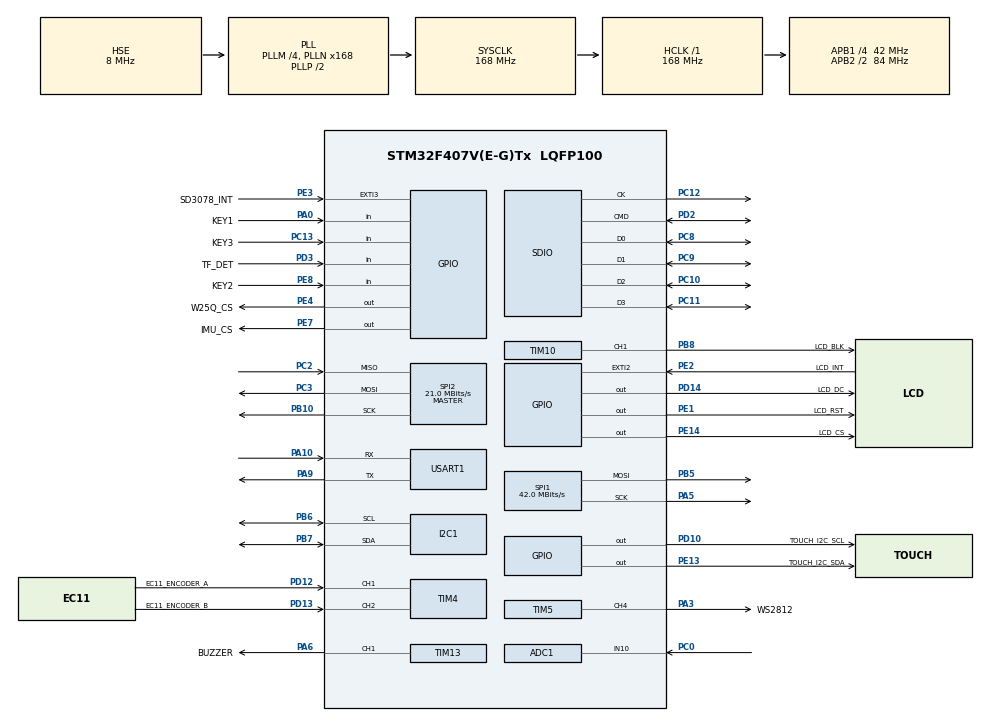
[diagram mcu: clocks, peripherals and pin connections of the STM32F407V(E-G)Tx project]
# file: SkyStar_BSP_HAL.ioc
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ADC1.Channel-0\#ChannelRegularConversion=ADC_CHANNEL_10
ADC1.NbrOfConversionFlag=1
ADC1.Rank-0\#ChannelRegularConversion=1
ADC1.SamplingTime-0\#ChannelRegularConversion=ADC_SAMPLETIME_3CYCLES
ADC1.master=1
Dma.Request0=USART1_RX
Dma.Request1=USART1_TX
Dma.Request2=TIM5_CH4/TRIG
Dma.Request3=SPI1_TX
Dma.Request4=SDIO_RX
Dma.Request5=SDIO_TX
Dma.SDIO_RX.4.Direction=DMA_PERIPH_TO_MEMORY
Dma.SDIO_RX.4.FIFOMode=DMA_FIFOMODE_ENABLE
Dma.SDIO_RX.4.FIFOThreshold=DMA_FIFO_THRESHOLD_FULL
Dma.SDIO_RX.4.Instance=DMA2_Stream6
Dma.SDIO_RX.4.MemBurst=DMA_MBURST_INC4
Dma.SDIO_RX.4.MemDataAlignment=DMA_MDATAALIGN_WORD
Dma.SDIO_RX.4.MemInc=DMA_MINC_ENABLE
Dma.SDIO_RX.4.Mode=DMA_PFCTRL
Dma.SDIO_RX.4.PeriphBurst=DMA_PBURST_INC4
Dma.SDIO_RX.4.PeriphDataAlignment=DMA_PDATAALIGN_WORD
Dma.SDIO_RX.4.PeriphInc=DMA_PINC_DISABLE
Dma.SDIO_RX.4.Priority=DMA_PRIORITY_LOW
Dma.SDIO_TX.5.Direction=DMA_MEMORY_TO_PERIPH
Dma.SDIO_TX.5.FIFOMode=DMA_FIFOMODE_ENABLE
Dma.SDIO_TX.5.FIFOThreshold=DMA_FIFO_THRESHOLD_FULL
Dma.SDIO_TX.5.Instance=DMA2_Stream3
Dma.SDIO_TX.5.MemBurst=DMA_MBURST_INC4
Dma.SDIO_TX.5.MemDataAlignment=DMA_MDATAALIGN_WORD
Dma.SDIO_TX.5.MemInc=DMA_MINC_ENABLE
Dma.SDIO_TX.5.Mode=DMA_PFCTRL
Dma.SDIO_TX.5.PeriphBurst=DMA_PBURST_INC4
Dma.SDIO_TX.5.PeriphDataAlignment=DMA_PDATAALIGN_WORD
Dma.SDIO_TX.5.PeriphInc=DMA_PINC_DISABLE
Dma.SDIO_TX.5.Priority=DMA_PRIORITY_LOW
Dma.SPI1_TX.3.Direction=DMA_MEMORY_TO_PERIPH
Dma.SPI1_TX.3.FIFOMode=DMA_FIFOMODE_DISABLE
Dma.SPI1_TX.3.Instance=DMA2_Stream5
Dma.SPI1_TX.3.MemDataAlignment=DMA_MDATAALIGN_BYTE
Dma.SPI1_TX.3.MemInc=DMA_MINC_ENABLE
Dma.SPI1_TX.3.Mode=DMA_NORMAL
Dma.SPI1_TX.3.PeriphDataAlignment=DMA_PDATAALIGN_BYTE
Dma.SPI1_TX.3.PeriphInc=DMA_PINC_DISABLE
Dma.SPI1_TX.3.Priority=DMA_PRIORITY_LOW
Dma.TIM5_CH4/TRIG.2.Direction=DMA_MEMORY_TO_PERIPH
Dma.TIM5_CH4/TRIG.2.FIFOMode=DMA_FIFOMODE_DISABLE
Dma.TIM5_CH4/TRIG.2.Instance=DMA1_Stream1
Dma.TIM5_CH4/TRIG.2.MemDataAlignment=DMA_MDATAALIGN_WORD
Dma.TIM5_CH4/TRIG.2.MemInc=DMA_MINC_ENABLE
Dma.TIM5_CH4/TRIG.2.Mode=DMA_NORMAL
Dma.TIM5_CH4/TRIG.2.PeriphDataAlignment=DMA_PDATAALIGN_WORD
Dma.TIM5_CH4/TRIG.2.PeriphInc=DMA_PINC_DISABLE
Dma.TIM5_CH4/TRIG.2.Priority=DMA_PRIORITY_LOW
Dma.USART1_RX.0.Direction=DMA_PERIPH_TO_MEMORY
Dma.USART1_RX.0.FIFOMode=DMA_FIFOMODE_DISABLE
Dma.USART1_RX.0.Instance=DMA2_Stream2
Dma.USART1_RX.0.MemDataAlignment=DMA_MDATAALIGN_BYTE
Dma.USART1_RX.0.MemInc=DMA_MINC_ENABLE
Dma.USART1_RX.0.Mode=DMA_CIRCULAR
Dma.USART1_RX.0.PeriphDataAlignment=DMA_PDATAALIGN_BYTE
Dma.USART1_RX.0.PeriphInc=DMA_PINC_DISABLE
Dma.USART1_RX.0.Priority=DMA_PRIORITY_LOW
Dma.USART1_TX.1.Direction=DMA_MEMORY_TO_PERIPH
Dma.USART1_TX.1.FIFOMode=DMA_FIFOMODE_DISABLE
Dma.USART1_TX.1.Instance=DMA2_Stream7
Dma.USART1_TX.1.MemDataAlignment=DMA_MDATAALIGN_BYTE
Dma.USART1_TX.1.MemInc=DMA_MINC_ENABLE
Dma.USART1_TX.1.Mode=DMA_NORMAL
Dma.USART1_TX.1.PeriphDataAlignment=DMA_PDATAALIGN_BYTE
Dma.USART1_TX.1.PeriphInc=DMA_PINC_DISABLE
Dma.USART1_TX.1.Priority=DMA_PRIORITY_LOW
FATFS.BSP.number=1
FATFS.USE_DMA_CODE_SD=1
FATFS0.BSP.STBoard=false
FATFS0.BSP.api=Unknown
FATFS0.BSP.instance=PD3
FATFS0.BSP.ip=GPIO
FATFS0.BSP.mode=Input
FATFS0.BSP.name=Detect_SDIO
FATFS0.BSP.solution=PD3
I2C1.I2C_Mode=I2C_Fast
Mcu.Family=STM32F4
Mcu.Name=STM32F407V(E-G)Tx
Mcu.Package=LQFP100
NVIC.DMA1_Stream1_IRQn=true\:0\:0\:false\:false\:true\:false\:true\:true
NVIC.DMA2_Stream2_IRQn=true\:0\:0\:false\:false\:true\:false\:true\:true
NVIC.DMA2_Stream3_IRQn=true\:0\:0\:false\:false\:true\:false\:true\:true
NVIC.DMA2_Stream5_IRQn=true\:0\:0\:false\:false\:true\:false\:true\:true
NVIC.DMA2_Stream6_IRQn=true\:0\:0\:false\:false\:true\:false\:true\:true
NVIC.DMA2_Stream7_IRQn=true\:0\:0\:false\:false\:true\:false\:true\:true
NVIC.EXTI2_IRQn=true\:3\:0\:true\:false\:true\:true\:true\:true
NVIC.EXTI3_IRQn=true\:3\:0\:true\:false\:true\:true\:true\:true
NVIC.PriorityGroup=NVIC_PRIORITYGROUP_4
NVIC.SDIO_IRQn=true\:0\:0\:false\:false\:true\:true\:true\:true
NVIC.USART1_IRQn=true\:0\:0\:false\:false\:true\:true\:true\:true
PA0-WKUP.GPIO_Label=KEY1
PA0-WKUP.GPIO_PuPd=GPIO_NOPULL
PA0-WKUP.Signal=GPIO_Input
PA10.Mode=Asynchronous
PA10.Signal=USART1_RX
PA13.Mode=Serial_Wire
PA13.Signal=SYS_JTMS-SWDIO
PA14.Mode=Serial_Wire
PA14.Signal=SYS_JTCK-SWCLK
PA3.GPIO_Label=WS2812
PA3.GPIO_Speed=GPIO_SPEED_FREQ_HIGH
PA3.Signal=S_TIM5_CH4
PA5.Mode=TX_Only_Simplex_Unidirect_Master
PA5.Signal=SPI1_SCK
PA6.GPIO_Label=BUZZER
PA6.GPIO_Speed=GPIO_SPEED_FREQ_HIGH
PA6.Signal=S_TIM13_CH1
PA9.Mode=Asynchronous
PA9.Signal=USART1_TX
PB10.Mode=Full_Duplex_Master
PB10.Signal=SPI2_SCK
PB5.Mode=TX_Only_Simplex_Unidirect_Master
PB5.Signal=SPI1_MOSI
PB6.Mode=I2C
PB6.Signal=I2C1_SCL
PB7.Mode=I2C
PB7.Signal=I2C1_SDA
PB8.GPIO_Label=LCD_BLK
PB8.Signal=S_TIM10_CH1
PC0.Signal=ADCx_IN10
PC10.Mode=SD_4_bits_Wide_bus
PC10.GPIO_PuPd=GPIO_PULL_UP
PC10.Signal=SDIO_D2
PC11.Mode=SD_4_bits_Wide_bus
PC11.GPIO_PuPd=GPIO_PULL_UP
PC11.Signal=SDIO_D3
PC12.Mode=SD_4_bits_Wide_bus
PC12.GPIO_PuPd=GPIO_PULL_UP
PC12.Signal=SDIO_CK
PC13-ANTI_TAMP.GPIO_Label=KEY3
PC13-ANTI_TAMP.GPIO_PuPd=GPIO_NOPULL
PC13-ANTI_TAMP.Signal=GPIO_Input
PC2.Mode=Full_Duplex_Master
PC2.Signal=SPI2_MISO
PC3.Mode=Full_Duplex_Master
PC3.Signal=SPI2_MOSI
PC8.Mode=SD_4_bits_Wide_bus
PC8.GPIO_PuPd=GPIO_PULL_UP
PC8.Signal=SDIO_D0
PC9.Mode=SD_4_bits_Wide_bus
PC9.GPIO_PuPd=GPIO_PULL_UP
PC9.Signal=SDIO_D1
PD10.GPIO_Label=TOUCH_I2C_SCL
PD10.GPIO_ModeDefaultOutputPP=GPIO_MODE_OUTPUT_OD
PD10.GPIO_PuPd=GPIO_PULLUP
PD10.GPIO_Speed=GPIO_SPEED_FREQ_HIGH
PD10.PinState=GPIO_PIN_SET
PD10.Signal=GPIO_Output
PD12.GPIO_Label=EC11_ENCODER_A
PD12.Signal=S_TIM4_CH1
PD13.GPIO_Label=EC11_ENCODER_B
PD13.Signal=S_TIM4_CH2
PD14.GPIO_Label=LCD_DC
PD14.GPIO_Speed=GPIO_SPEED_FREQ_VERY_HIGH
PD14.PinState=GPIO_PIN_SET
PD14.Signal=GPIO_Output
PD2.Mode=SD_4_bits_Wide_bus
PD2.GPIO_PuPd=GPIO_PULL_UP
PD2.Signal=SDIO_CMD
PD3.GPIO_Label=TF_DET
PD3.GPIO_PuPd=GPIO_PULLUP
PD3.Signal=GPIO_Input
PE1.GPIO_Label=LCD_RST
PE1.GPIO_Speed=GPIO_SPEED_FREQ_LOW
PE1.PinState=GPIO_PIN_SET
PE1.Signal=GPIO_Output
PE13.GPIO_Label=TOUCH_I2C_SDA
PE13.GPIO_ModeDefaultOutputPP=GPIO_MODE_OUTPUT_OD
PE13.GPIO_PuPd=GPIO_PULLUP
PE13.GPIO_Speed=GPIO_SPEED_FREQ_HIGH
PE13.PinState=GPIO_PIN_SET
PE13.Signal=GPIO_Output
PE14.GPIO_Label=LCD_CS
PE14.GPIO_Speed=GPIO_SPEED_FREQ_VERY_HIGH
PE14.PinState=GPIO_PIN_SET
PE14.Signal=GPIO_Output
PE2.GPIO_Label=LCD_INT
PE2.GPIO_ModeDefaultEXTI=GPIO_MODE_IT_FALLING
PE2.GPIO_PuPd=GPIO_PULLUP
PE2.Signal=GPXTI2
PE3.GPIO_Label=SD3078_INT
PE3.GPIO_ModeDefaultEXTI=GPIO_MODE_IT_FALLING
PE3.GPIO_PuPd=GPIO_PULLUP
PE3.Signal=GPXTI3
PE4.GPIO_Label=W25Q_CS
PE4.GPIO_Speed=GPIO_SPEED_FREQ_VERY_HIGH
PE4.PinState=GPIO_PIN_SET
PE4.Signal=GPIO_Output
PE7.GPIO_Label=IMU_CS
PE7.GPIO_ModeDefaultOutputPP=GPIO_MODE_OUTPUT_PP
PE7.GPIO_Speed=GPIO_SPEED_FREQ_VERY_HIGH
PE7.PinState=GPIO_PIN_SET
PE7.Signal=GPIO_Output
PE8.GPIO_Label=KEY2
PE8.GPIO_PuPd=GPIO_NOPULL
PE8.Signal=GPIO_Input
PH0-OSC_IN.Mode=HSE-External-Oscillator
PH0-OSC_IN.Signal=RCC_OSC_IN
PH1-OSC_OUT.Mode=HSE-External-Oscillator
PH1-OSC_OUT.Signal=RCC_OSC_OUT
ProjectManager.HeapSize=0x1000
ProjectManager.StackSize=0x2000
ProjectManager.TargetToolchain=MDK-ARM V5.32
RCC.48MHZClocksFreq_Value=42000000
RCC.AHBFreq_Value=168000000
RCC.APB1CLKDivider=RCC_HCLK_DIV4
RCC.APB1Freq_Value=42000000
RCC.APB1TimFreq_Value=84000000
RCC.APB2CLKDivider=RCC_HCLK_DIV2
RCC.APB2Freq_Value=84000000
RCC.APB2TimFreq_Value=168000000
RCC.CortexFreq_Value=168000000
RCC.HCLKFreq_Value=168000000
RCC.HSE_VALUE=8000000
RCC.HSI_VALUE=16000000
RCC.LSE_VALUE=32768
RCC.PLLM=4
RCC.PLLN=168
RCC.PLLQ=8
RCC.PLLSourceVirtual=RCC_PLLSOURCE_HSE
RCC.SYSCLKFreq_VALUE=168000000
RCC.SYSCLKSource=RCC_SYSCLKSOURCE_PLLCLK
RCC.VCOOutputFreq_Value=336000000
SDIO.ClockDiv=8
SH.ADCx_IN10.0=ADC1_IN10,IN10
SH.S_TIM10_CH1.0=TIM10_CH1,PWM Generation1 CH1
SH.S_TIM13_CH1.0=TIM13_CH1,PWM Generation1 CH1
SH.S_TIM4_CH1.0=TIM4_CH1,Encoder_Interface
SH.S_TIM4_CH2.0=TIM4_CH2,Encoder_Interface
SH.S_TIM5_CH4.0=TIM5_CH4,PWM Generation4 CH4
SPI1.CalculateBaudRate=42.0 MBits/s
SPI1.Direction=SPI_DIRECTION_2LINES
SPI1.Mode=SPI_MODE_MASTER
SPI1.VirtualType=VM_MASTER
SPI2.CalculateBaudRate=21.0 MBits/s
SPI2.Direction=SPI_DIRECTION_2LINES
SPI2.Mode=SPI_MODE_MASTER
SPI2.VirtualType=VM_MASTER
TIM10.AutoReloadPreload=TIM_AUTORELOAD_PRELOAD_ENABLE
TIM10.Channel=TIM_CHANNEL_1
TIM10.Period=100-1
TIM10.Polarity_CH1=TIM_OCPOLARITY_LOW
TIM10.Prescaler=168-1
TIM13.Channel=TIM_CHANNEL_1
TIM4.IC1Filter=15
TIM4.IC2Filter=15
TIM5.Channel-PWM\ Generation4\ CH4=TIM_CHANNEL_4
USART1.VirtualMode=VM_ASYNC
VP_FATFS_VS_SDIO.Mode=SDIO
VP_TIM10_VS_ClockSourceINT.Mode=Enable_Timer
VP_TIM13_VS_ClockSourceINT.Mode=Enable_Timer
VP_TIM5_VS_ClockSourceINT.Mode=Internal
board=custom

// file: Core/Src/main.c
/* USER CODE BEGIN Header */
/**
  ******************************************************************************
  * @file           : main.c
  * @brief          : Main program body
  ******************************************************************************
  * @attention
  *
  * Copyright (c) 2026 STMicroelectronics.
  * All rights reserved.
  *
  * This software is licensed under terms that can be found in the LICENSE file
  * in the root directory of this software component.
  * If no LICENSE file comes with this software, it is provided AS-IS.
  *
  ******************************************************************************
  */
/* USER CODE END Header */
#include "main.h"
#include "adc.h"
#include "dma.h"
#include "fatfs.h"
#include "i2c.h"
#include "sdio.h"
#include "spi.h"
#include "tim.h"
#include "usart.h"
#include "gpio.h"

/* USER CODE BEGIN Includes */
#include "bsp_board.h"
#include "app_main.h"
/* USER CODE END Includes */

void SystemClock_Config(void);

int main(void)
{

  /* MCU Configuration--------------------------------------------------------*/

  /* Reset of all peripherals, Initializes the Flash interface and the Systick. */
  HAL_Init();

  /* Configure the system clock */
  SystemClock_Config();

  /* Initialize all configured peripherals */
  MX_GPIO_Init();
  MX_DMA_Init();
  MX_USART1_UART_Init();
  MX_TIM5_Init();
  MX_TIM13_Init();
  MX_I2C1_Init();
  MX_SPI1_Init();
  MX_SPI2_Init();
  MX_TIM10_Init();
  MX_ADC1_Init();
  MX_TIM4_Init();
  MX_SDIO_SD_Init();
  MX_FATFS_Init();
  /* USER CODE BEGIN 2 */
    extern void multi_timer_port_init(void);
    multi_timer_port_init();
    app_main_init();
  /* USER CODE END 2 */

  /* Infinite loop */
  while (1)
  {

    /* USER CODE BEGIN 3 */
    app_main_process();
  }
  /* USER CODE END 3 */
}

void SystemClock_Config(void)
{
  RCC_OscInitTypeDef RCC_OscInitStruct = {0};
  RCC_ClkInitTypeDef RCC_ClkInitStruct = {0};

  /** Configure the main internal regulator output voltage
  */
  __HAL_RCC_PWR_CLK_ENABLE();
  __HAL_PWR_VOLTAGESCALING_CONFIG(PWR_REGULATOR_VOLTAGE_SCALE1);

  /** Initializes the RCC Oscillators according to the specified parameters
  * in the RCC_OscInitTypeDef structure.
  */
  RCC_OscInitStruct.OscillatorType = RCC_OSCILLATORTYPE_HSE;
  RCC_OscInitStruct.HSEState = RCC_HSE_ON;
  RCC_OscInitStruct.PLL.PLLState = RCC_PLL_ON;
  RCC_OscInitStruct.PLL.PLLSource = RCC_PLLSOURCE_HSE;
  RCC_OscInitStruct.PLL.PLLM = 4;
  RCC_OscInitStruct.PLL.PLLN = 168;
  RCC_OscInitStruct.PLL.PLLP = RCC_PLLP_DIV2;
  RCC_OscInitStruct.PLL.PLLQ = 8;
  if (HAL_RCC_OscConfig(&RCC_OscInitStruct) != HAL_OK)
  {
    Error_Handler();
  }

  /** Initializes the CPU, AHB and APB buses clocks
  */
  RCC_ClkInitStruct.ClockType = RCC_CLOCKTYPE_HCLK|RCC_CLOCKTYPE_SYSCLK
                              |RCC_CLOCKTYPE_PCLK1|RCC_CLOCKTYPE_PCLK2;
  RCC_ClkInitStruct.SYSCLKSource = RCC_SYSCLKSOURCE_PLLCLK;
  RCC_ClkInitStruct.AHBCLKDivider = RCC_SYSCLK_DIV1;
  RCC_ClkInitStruct.APB1CLKDivider = RCC_HCLK_DIV4;
  RCC_ClkInitStruct.APB2CLKDivider = RCC_HCLK_DIV2;

  if (HAL_RCC_ClockConfig(&RCC_ClkInitStruct, FLASH_LATENCY_5) != HAL_OK)
  {
    Error_Handler();
  }
}

void Error_Handler(void)
{
    __disable_irq();
    while (1)
    {
    }
}
